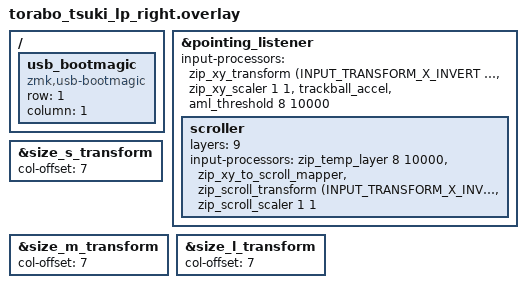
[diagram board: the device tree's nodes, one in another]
#include "torabo_tsuki_lp.dtsi"
#include <input/processors.dtsi>
#include <dt-bindings/zmk/input_transform.h>

&pointing_listener {
    input-processors =
        <&zip_xy_transform (INPUT_TRANSFORM_X_INVERT | INPUT_TRANSFORM_Y_INVERT)>,
        <&zip_xy_scaler 1 1>,
        <&trackball_accel>,             // 速さに応じた倍率 (カーソルの加速)
        <&aml_threshold 8 10000>;       // 8 = MOUS (マウス移動レイヤーを自動有効化。わずかな動きでは発動しない)

    scroller {
        layers = <9>;
        input-processors =
            <&zip_temp_layer 8 10000>,      // 8 = MOUS (スクロール中も MOUS を維持する)
            <&zip_xy_to_scroll_mapper>,
            <&zip_scroll_transform (INPUT_TRANSFORM_X_INVERT)>,
            <&zip_scroll_scaler 1 1>;
    };
};

&size_s_transform {
    col-offset = <7>;
};

&size_m_transform {
    col-offset = <7>;
};

&size_l_transform {
    col-offset = <7>;
};

// P を押したまま USB ケーブルを挿すと、ブートローダになる (src/usb_bootmagic.c)
/ {
    usb_bootmagic {
        compatible = "zmk,usb-bootmagic";
        row = <1>;
        column = <1>;
    };
};
